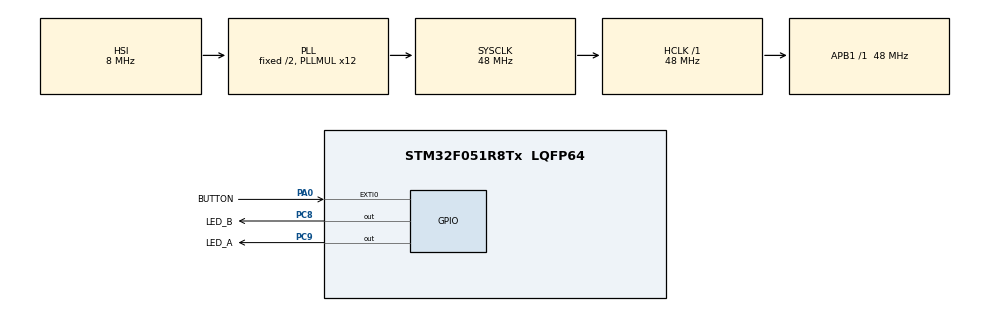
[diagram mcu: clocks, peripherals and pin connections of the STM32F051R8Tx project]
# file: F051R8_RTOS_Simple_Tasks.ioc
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Mcu.Family=STM32F0
VP_SYS_VS_tim6.Mode=TIM6
FREERTOS.Tasks01=Task_A,24,64,Task_A_Main,Default,NULL,Dynamic,NULL,NULL;Task_B,24,64,Task_B_Main,Default,NULL,Dynamic,NULL,NULL;Task_C,24,64,Task_C_Main,Default,NULL,Dynamic,NULL,NULL
PC9.GPIO_Label=LED_A
NVIC.TIM6_DAC_IRQn=true\:0\:0\:false\:false\:true\:false\:false\:true
PA14.GPIO_Label=SWCLK
PA0.GPIO_Label=BUTTON
PC8.Signal=GPIO_Output
RCC.SYSCLKSource=RCC_SYSCLKSOURCE_PLLCLK
ProjectManager.StackSize=0x400
VP_FREERTOS_VS_CMSIS_V2.Mode=CMSIS_V2
PC8.GPIO_Label=LED_B
PA13.Signal=SYS_SWDIO
ProjectManager.TargetToolchain=STM32CubeIDE
FREERTOS.configTIMER_TASK_STACK_DEPTH=64
RCC.HCLKFreq_Value=48000000
FREERTOS.configMINIMAL_STACK_SIZE=64
RCC.AHBFreq_Value=48000000
board=STM32F0DISCOVERY
RCC.PLLMUL=RCC_PLL_MUL12
FREERTOS.configENABLE_BACKWARD_COMPATIBILITY=0
PA14.Mode=Serial_Wire
PA0.GPIO_ModeDefaultEXTI=GPIO_MODE_EVT_RISING
PA13.Mode=Serial_Wire
Mcu.Name=STM32F051R8Tx
FREERTOS.configTOTAL_HEAP_SIZE=1536
PA13.GPIO_Label=SWDIO
PA0.Signal=GPXTI0
RCC.SYSCLKFreq_VALUE=48000000
Mcu.Package=LQFP64
NVIC.TimeBase=TIM6_DAC_IRQn
NVIC.TimeBaseIP=TIM6
PA14.Signal=SYS_SWCLK
ProjectManager.HeapSize=0x200
FREERTOS.Timers01=Timer5s,Timer5sCallback,osTimerOnce,Default,NULL,Dynamic,NULL
RCC.APB1TimFreq_Value=48000000
PC9.Signal=GPIO_Output
RCC.APB1Freq_Value=48000000

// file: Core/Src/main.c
/* USER CODE BEGIN Header */
/**
  ******************************************************************************
  * @file           : main.c
  * @brief          : Main program body
  ******************************************************************************
  * @attention
  *
  * <h2><center>&copy; Copyright (c) 2021 STMicroelectronics.
  * All rights reserved.</center></h2>
  *
  * This software component is licensed by ST under BSD 3-Clause license,
  * the "License"; You may not use this file except in compliance with the
  * License. You may obtain a copy of the License at:
  *                        opensource.org/licenses/BSD-3-Clause
  *
  ******************************************************************************
  */
/* USER CODE END Header */
#include "main.h"
#include "cmsis_os.h"

/* USER CODE BEGIN PD */
#define USE_BUTTON_LATENCY
/* USER CODE END PD */

/* Definitions for Task_A */
osThreadId_t Task_AHandle;
const osThreadAttr_t Task_A_attributes = {
  .name = "Task_A",
  .stack_size = 64 * 4,
  .priority = (osPriority_t) osPriorityNormal,
};
/* Definitions for Task_B */
osThreadId_t Task_BHandle;
const osThreadAttr_t Task_B_attributes = {
  .name = "Task_B",
  .stack_size = 64 * 4,
  .priority = (osPriority_t) osPriorityNormal,
};
/* Definitions for Task_C */
osThreadId_t Task_CHandle;
const osThreadAttr_t Task_C_attributes = {
  .name = "Task_C",
  .stack_size = 64 * 4,
  .priority = (osPriority_t) osPriorityNormal,
};
/* Definitions for Timer5s */
osTimerId_t Timer5sHandle;
const osTimerAttr_t Timer5s_attributes = {
  .name = "Timer5s"
};
/* USER CODE BEGIN PV */
char isButtonPressed = 0;
/* USER CODE END PV */

void SystemClock_Config(void);
static void MX_GPIO_Init(void);
void Task_A_Main(void *argument);
void Task_B_Main(void *argument);
void Task_C_Main(void *argument);
void Timer5sCallback(void *argument);

int main(void)
{

  /* MCU Configuration--------------------------------------------------------*/

  /* Reset of all peripherals, Initializes the Flash interface and the Systick. */
  HAL_Init();

  /* Configure the system clock */
  SystemClock_Config();

  /* Initialize all configured peripherals */
  MX_GPIO_Init();

  /* Init scheduler */
  osKernelInitialize();

  /* Create the timer(s) */
  /* creation of Timer5s */
  Timer5sHandle = osTimerNew(Timer5sCallback, osTimerOnce, NULL, &Timer5s_attributes);

  /* Create the thread(s) */
  /* creation of Task_A */
  Task_AHandle = osThreadNew(Task_A_Main, NULL, &Task_A_attributes);

  /* creation of Task_B */
  Task_BHandle = osThreadNew(Task_B_Main, NULL, &Task_B_attributes);

  /* creation of Task_C */
  Task_CHandle = osThreadNew(Task_C_Main, NULL, &Task_C_attributes);

  /* Start scheduler */
  osKernelStart();

  /* We should never get here as control is now taken by the scheduler */
  /* Infinite loop */
  while (1)
  {

  }
}

void SystemClock_Config(void)
{
  RCC_OscInitTypeDef RCC_OscInitStruct = {0};
  RCC_ClkInitTypeDef RCC_ClkInitStruct = {0};

  /** Initializes the RCC Oscillators according to the specified parameters
  * in the RCC_OscInitTypeDef structure.
  */
  RCC_OscInitStruct.OscillatorType = RCC_OSCILLATORTYPE_HSI;
  RCC_OscInitStruct.HSIState = RCC_HSI_ON;
  RCC_OscInitStruct.HSICalibrationValue = RCC_HSICALIBRATION_DEFAULT;
  RCC_OscInitStruct.PLL.PLLState = RCC_PLL_ON;
  RCC_OscInitStruct.PLL.PLLSource = RCC_PLLSOURCE_HSI;
  RCC_OscInitStruct.PLL.PLLMUL = RCC_PLL_MUL12;
  RCC_OscInitStruct.PLL.PREDIV = RCC_PREDIV_DIV1;
  if (HAL_RCC_OscConfig(&RCC_OscInitStruct) != HAL_OK)
  {
    Error_Handler();
  }
  /** Initializes the CPU, AHB and APB buses clocks
  */
  RCC_ClkInitStruct.ClockType = RCC_CLOCKTYPE_HCLK|RCC_CLOCKTYPE_SYSCLK
                              |RCC_CLOCKTYPE_PCLK1;
  RCC_ClkInitStruct.SYSCLKSource = RCC_SYSCLKSOURCE_PLLCLK;
  RCC_ClkInitStruct.AHBCLKDivider = RCC_SYSCLK_DIV1;
  RCC_ClkInitStruct.APB1CLKDivider = RCC_HCLK_DIV1;

  if (HAL_RCC_ClockConfig(&RCC_ClkInitStruct, FLASH_LATENCY_1) != HAL_OK)
  {
    Error_Handler();
  }
}

static void MX_GPIO_Init(void)
{
  GPIO_InitTypeDef GPIO_InitStruct = {0};

  /* GPIO Ports Clock Enable */
  __HAL_RCC_GPIOA_CLK_ENABLE();
  __HAL_RCC_GPIOC_CLK_ENABLE();

  /*Configure GPIO pin Output Level */
  HAL_GPIO_WritePin(GPIOC, LED_B_Pin|LED_A_Pin, GPIO_PIN_RESET);

  /*Configure GPIO pin : BUTTON_Pin */
  GPIO_InitStruct.Pin = BUTTON_Pin;
  GPIO_InitStruct.Mode = GPIO_MODE_EVT_RISING;
  GPIO_InitStruct.Pull = GPIO_NOPULL;
  HAL_GPIO_Init(BUTTON_GPIO_Port, &GPIO_InitStruct);

  /*Configure GPIO pins : LED_B_Pin LED_A_Pin */
  GPIO_InitStruct.Pin = LED_B_Pin|LED_A_Pin;
  GPIO_InitStruct.Mode = GPIO_MODE_OUTPUT_PP;
  GPIO_InitStruct.Pull = GPIO_NOPULL;
  GPIO_InitStruct.Speed = GPIO_SPEED_FREQ_LOW;
  HAL_GPIO_Init(GPIOC, &GPIO_InitStruct);

}

void Task_A_Main(void *argument)
{
  /* USER CODE BEGIN 5 */
  /* Infinite loop */
  for(;;)
  {
    if (!isButtonPressed) HAL_GPIO_TogglePin(LED_A_GPIO_Port, LED_A_Pin);
    osDelay(100);
  }
  /* USER CODE END 5 */
}

void Task_B_Main(void *argument)
{
  /* USER CODE BEGIN Task_B_Main */
  /* Infinite loop */
  for(;;)
  {
    if (!isButtonPressed) HAL_GPIO_TogglePin(LED_B_GPIO_Port, LED_B_Pin);
    osDelay(200);
  }
  /* USER CODE END Task_B_Main */
}

void Task_C_Main(void *argument)
{
  /* USER CODE BEGIN Task_C_Main */
  /* Infinite loop */
  for(;;)
  {
#ifndef USE_BUTTON_LATENCY
    isButtonPressed = (HAL_GPIO_ReadPin(BUTTON_GPIO_Port, BUTTON_Pin) == GPIO_PIN_SET);
#else
    if(HAL_GPIO_ReadPin(BUTTON_GPIO_Port, BUTTON_Pin) == GPIO_PIN_SET) {
      isButtonPressed = 1;
      osTimerStart(Timer5sHandle, 5000);
    }
#endif
    osDelay(100);
  }
  /* USER CODE END Task_C_Main */
}

/* Timer5sCallback function */
void Timer5sCallback(void *argument)
{
  /* USER CODE BEGIN Timer5sCallback */
  isButtonPressed = 0;
  /* USER CODE END Timer5sCallback */
}

 /**
  * @brief  Period elapsed callback in non blocking mode
  * @note   This function is called  when TIM6 interrupt took place, inside
  * HAL_TIM_IRQHandler(). It makes a direct call to HAL_IncTick() to increment
  * a global variable "uwTick" used as application time base.
  * @param  htim : TIM handle
  * @retval None
  */
void HAL_TIM_PeriodElapsedCallback(TIM_HandleTypeDef *htim)
{
  if (htim->Instance == TIM6) {
    HAL_IncTick();
  }
}

void Error_Handler(void)
{
  __disable_irq();
  while (1)
  {
  }
}

/************************ (C) COPYRIGHT STMicroelectronics *****END OF FILE****/
